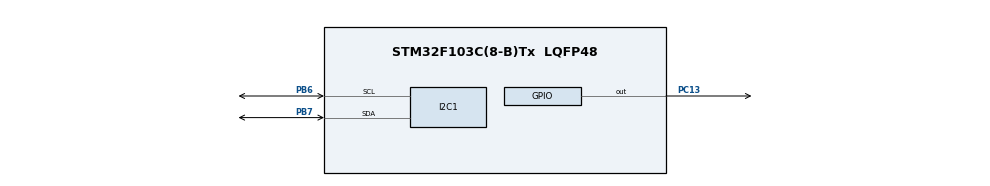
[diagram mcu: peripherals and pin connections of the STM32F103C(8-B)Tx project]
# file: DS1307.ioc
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Mcu.Family=STM32F1
Mcu.Name=STM32F103C(8-B)Tx
Mcu.Package=LQFP48
NVIC.I2C1_EV_IRQn=true\:0\:0\:false\:false\:true\:true\:true\:true
NVIC.PriorityGroup=NVIC_PRIORITYGROUP_4
PA13.Mode=Serial_Wire
PA13.Signal=SYS_JTMS-SWDIO
PA14.Mode=Serial_Wire
PA14.Signal=SYS_JTCK-SWCLK
PB6.Mode=I2C
PB6.Signal=I2C1_SCL
PB7.Mode=I2C
PB7.Signal=I2C1_SDA
PC13-TAMPER-RTC.Signal=GPIO_Output
ProjectManager.HeapSize=0x200
ProjectManager.StackSize=0x400
ProjectManager.TargetToolchain=STM32CubeIDE
RCC.APB1Freq_Value=8000000
RCC.APB2Freq_Value=8000000
board=custom

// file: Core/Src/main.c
/* USER CODE BEGIN Header */
/**
  ******************************************************************************
  * @file           : main.c
  * @brief          : Main program body
  ******************************************************************************
  * @attention
  *
  * Copyright (c) 2024 STMicroelectronics.
  * All rights reserved.
  *
  * This software is licensed under terms that can be found in the LICENSE file
  * in the root directory of this software component.
  * If no LICENSE file comes with this software, it is provided AS-IS.
  *
  ******************************************************************************
  */
/* USER CODE END Header */
#include "main.h"

/* USER CODE BEGIN PD */
#define DS1307_ADDR 0x68 << 1

/* USER CODE END PD */

 /* Private macro -------------------------------------------------------------*/
/* USER CODE BEGIN PM */
typedef struct
{
	uint8_t hour;
	uint8_t min;
	uint8_t sec;
	uint8_t date;
	uint8_t day;
	uint8_t month;
	uint8_t year;

}DS1307_TypeDef;
/* USER CODE END PM */

I2C_HandleTypeDef hi2c1;

/* USER CODE BEGIN PV */
uint8_t Bcd2Dec (uint8_t data);
uint8_t Dec2Bcd (uint8_t data);
uint8_t revBuff[7];
uint8_t tranBuff[7];
uint8_t status=0;
DS1307_TypeDef DS1307_TimeNow;
DS1307_TypeDef DS1307_TimeSet;
/* USER CODE END PV */

void SystemClock_Config(void);
static void MX_GPIO_Init(void);
static void MX_I2C1_Init(void);
/* USER CODE BEGIN PFP */
uint8_t Bcd2Dec (uint8_t data)
{
	return (data >> 4)*10 + (data&0x0f);
}
uint8_t Dec2Bcd (uint8_t data)
{
	return (data / 10)<<10 | (data%0x0f);
}
/* USER CODE END PFP */

int main(void)
{

  /* MCU Configuration--------------------------------------------------------*/

  /* Reset of all peripherals, Initializes the Flash interface and the Systick. */
  HAL_Init();

  /* USER CODE BEGIN Init */
  HAL_GPIO_WritePin(GPIOC,GPIO_PIN_13,1);
  /* USER CODE END Init */

  /* Configure the system clock */
  SystemClock_Config();

  /* Initialize all configured peripherals */
  MX_GPIO_Init();
  MX_I2C1_Init();
  /* USER CODE BEGIN 2 */
  for(uint8_t i=0; i<255 ; i++)
  {
	  if(HAL_I2C_IsDeviceReady(&hi2c1,i,1,10) == HAL_OK)
	  {
		  status = i;
		  HAL_GPIO_WritePin(GPIOC,GPIO_PIN_13,0);
	  }
  }

  tranBuff[0] = Dec2Bcd(00);
  tranBuff[1] = Dec2Bcd(50);
  tranBuff[2] = Dec2Bcd(15);

  tranBuff[4] = Dec2Bcd(7);
  tranBuff[5] = Dec2Bcd(14);
  tranBuff[6] = Dec2Bcd(2);
  tranBuff[7] = Dec2Bcd(22);
  HAL_I2C_Mem_Write_IT(&hi2c1,DS1307_ADDR,0x00,I2C_MEMADD_SIZE_8BIT,tranBuff,7);
  /* USER CODE END 2 */

  /* Infinite loop */
  while (1)
  {

    /* USER CODE BEGIN 3 */
	  HAL_I2C_Mem_Read_IT(&hi2c1,DS1307_ADDR,0x00,I2C_MEMADD_SIZE_8BIT,revBuff,7);
	  HAL_Delay(1000);
  }
  /* USER CODE END 3 */
}

void SystemClock_Config(void)
{
  RCC_OscInitTypeDef RCC_OscInitStruct = {0};
  RCC_ClkInitTypeDef RCC_ClkInitStruct = {0};

  /** Initializes the RCC Oscillators according to the specified parameters
  * in the RCC_OscInitTypeDef structure.
  */
  RCC_OscInitStruct.OscillatorType = RCC_OSCILLATORTYPE_HSI;
  RCC_OscInitStruct.HSIState = RCC_HSI_ON;
  RCC_OscInitStruct.HSICalibrationValue = RCC_HSICALIBRATION_DEFAULT;
  RCC_OscInitStruct.PLL.PLLState = RCC_PLL_NONE;
  if (HAL_RCC_OscConfig(&RCC_OscInitStruct) != HAL_OK)
  {
    Error_Handler();
  }

  /** Initializes the CPU, AHB and APB buses clocks
  */
  RCC_ClkInitStruct.ClockType = RCC_CLOCKTYPE_HCLK|RCC_CLOCKTYPE_SYSCLK
                              |RCC_CLOCKTYPE_PCLK1|RCC_CLOCKTYPE_PCLK2;
  RCC_ClkInitStruct.SYSCLKSource = RCC_SYSCLKSOURCE_HSI;
  RCC_ClkInitStruct.AHBCLKDivider = RCC_SYSCLK_DIV1;
  RCC_ClkInitStruct.APB1CLKDivider = RCC_HCLK_DIV1;
  RCC_ClkInitStruct.APB2CLKDivider = RCC_HCLK_DIV1;

  if (HAL_RCC_ClockConfig(&RCC_ClkInitStruct, FLASH_LATENCY_0) != HAL_OK)
  {
    Error_Handler();
  }
}

static void MX_I2C1_Init(void)
{

  hi2c1.Instance = I2C1;
  hi2c1.Init.ClockSpeed = 100000;
  hi2c1.Init.DutyCycle = I2C_DUTYCYCLE_2;
  hi2c1.Init.OwnAddress1 = 0;
  hi2c1.Init.AddressingMode = I2C_ADDRESSINGMODE_7BIT;
  hi2c1.Init.DualAddressMode = I2C_DUALADDRESS_DISABLE;
  hi2c1.Init.OwnAddress2 = 0;
  hi2c1.Init.GeneralCallMode = I2C_GENERALCALL_DISABLE;
  hi2c1.Init.NoStretchMode = I2C_NOSTRETCH_DISABLE;
  if (HAL_I2C_Init(&hi2c1) != HAL_OK)
  {
    Error_Handler();
  }

}

static void MX_GPIO_Init(void)
{
  GPIO_InitTypeDef GPIO_InitStruct = {0};

  /* GPIO Ports Clock Enable */
  __HAL_RCC_GPIOC_CLK_ENABLE();
  __HAL_RCC_GPIOA_CLK_ENABLE();
  __HAL_RCC_GPIOB_CLK_ENABLE();

  /*Configure GPIO pin Output Level */
  HAL_GPIO_WritePin(GPIOC, GPIO_PIN_13, GPIO_PIN_RESET);

  /*Configure GPIO pin : PC13 */
  GPIO_InitStruct.Pin = GPIO_PIN_13;
  GPIO_InitStruct.Mode = GPIO_MODE_OUTPUT_PP;
  GPIO_InitStruct.Pull = GPIO_NOPULL;
  GPIO_InitStruct.Speed = GPIO_SPEED_FREQ_LOW;
  HAL_GPIO_Init(GPIOC, &GPIO_InitStruct);

}

/* USER CODE BEGIN 4 */
void HAL_I2C_MemRxCpltCallback(I2C_HandleTypeDef *hi2c)
{
  /* Prevent unused argument(s) compilation warning */
  UNUSED(hi2c);

  if(hi2c -> Instance == I2C1)
  {
	  DS1307_TimeNow.sec = Bcd2Dec(revBuff[0]);
	  DS1307_TimeNow.min = Bcd2Dec(revBuff[1]);
	  DS1307_TimeNow.hour = Bcd2Dec(revBuff[2]);

	  DS1307_TimeNow.date = Bcd2Dec(revBuff[3]);
	  DS1307_TimeNow.day = Bcd2Dec(revBuff[4]);
	  DS1307_TimeNow.month = Bcd2Dec(revBuff[5]);
	  DS1307_TimeNow.year = Bcd2Dec(revBuff[6]);

  }
}
/* USER CODE END 4 */

void Error_Handler(void)
{
  __disable_irq();
  while (1)
  {
  }
}
